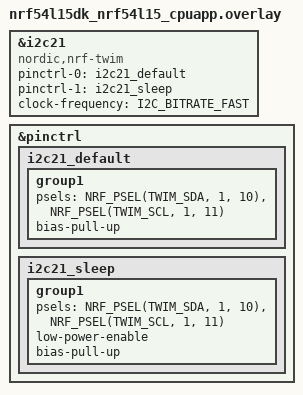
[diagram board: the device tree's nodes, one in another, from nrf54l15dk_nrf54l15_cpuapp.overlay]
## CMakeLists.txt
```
cmake_minimum_required(VERSION 3.20.0)
find_package(Zephyr REQUIRED HINTS $ENV{ZEPHYR_BASE})

project(i2c_hardtest)

target_sources(app PRIVATE src/main.c)
```

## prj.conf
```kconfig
# ==== Zephyr I2C設定（nRF54L15DK, NCS v3.2.4 向け）====

# Zephyr標準I2Cドライバを有効化
CONFIG_I2C=y

# デバッグ出力
CONFIG_PRINTK=y
CONFIG_LOG=y
CONFIG_LOG_DEFAULT_LEVEL=3

# スタック余裕
CONFIG_MAIN_STACK_SIZE=2048

# アサート
CONFIG_ASSERT=y

# UART コンソール
CONFIG_SERIAL=y
CONFIG_CONSOLE=y
CONFIG_UART_CONSOLE=y
```

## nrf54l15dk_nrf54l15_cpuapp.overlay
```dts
/* I2C設定: TWIM21を使用（UART20との競合回避） */

&i2c21 {
    status = "okay";
    compatible = "nordic,nrf-twim";
    pinctrl-0 = <&i2c21_default>;
    pinctrl-1 = <&i2c21_sleep>;
    pinctrl-names = "default", "sleep";
    clock-frequency = <I2C_BITRATE_FAST>; /* 400kHz */
};

&pinctrl {
    i2c21_default: i2c21_default {
        group1 {
            psels = <NRF_PSEL(TWIM_SDA, 1, 10)>,
                    <NRF_PSEL(TWIM_SCL, 1, 11)>;
            bias-pull-up;  /* ★ 内蔵プルアップを有効化 */
        };
    };

    i2c21_sleep: i2c21_sleep {
        group1 {
            psels = <NRF_PSEL(TWIM_SDA, 1, 10)>,
                    <NRF_PSEL(TWIM_SCL, 1, 11)>;
            low-power-enable;
            bias-pull-up;  /* ★ スリープ時もプルアップを維持 */
        };
    };
};
```

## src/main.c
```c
#include <zephyr/kernel.h>
#include <zephyr/device.h>
#include <zephyr/drivers/i2c.h>
#include <zephyr/sys/printk.h>

/* I2Cデバイスノード（TWIM21を使用） */
#define I2C_DEV_NODE DT_NODELABEL(i2c21)

/* スレーブアドレス（7bit） */
#define I2C_ADDR_7BIT  0x50

/* 送信データ（0～255） */
static uint8_t tx_buf[256];

int main(void)
{
    const struct device *i2c_dev;
    int ret;
    uint32_t success_count = 0;
    uint32_t error_count = 0;

    printk("=== nRF54L15 I2C Test (TWIM21) ===\n");

    /* 送信データ初期化 */
    for (uint32_t i = 0; i < sizeof(tx_buf); i++) {
        tx_buf[i] = (uint8_t)i;
    }

    /* I2Cデバイス取得 */
    i2c_dev = DEVICE_DT_GET(I2C_DEV_NODE);
    
    if (!device_is_ready(i2c_dev)) {
        printk("ERROR: I2C device not ready\n");
        return -1;
    }

    printk("I2C device ready: %s\n", i2c_dev->name);

    /* I2C設定を表示 */
    uint32_t i2c_cfg;
    ret = i2c_get_config(i2c_dev, &i2c_cfg);
    if (ret == 0) {
        uint32_t speed = I2C_SPEED_GET(i2c_cfg);
        const char *speed_str;
        switch (speed) {
            case I2C_SPEED_STANDARD:   speed_str = "100kHz"; break;
            case I2C_SPEED_FAST:       speed_str = "400kHz"; break;
            case I2C_SPEED_FAST_PLUS:  speed_str = "1MHz"; break;
            default:                   speed_str = "unknown"; break;
        }
        printk("I2C speed: %s\n", speed_str);
    }


    printk("Starting I2C transmission to addr 0x%02X...\n", I2C_ADDR_7BIT);

    /* 連続送信 */
    while (1) {


        for(int i=0;i!=sizeof(tx_buf);i++){
            ret = i2c_write(i2c_dev, &tx_buf[i], 1, I2C_ADDR_7BIT);
            
            if (ret == 0) {
                success_count++;
                if (success_count % 100 == 0) {
                    printk("OK: %u, ERR: %u\n", success_count, error_count);
                }
            } else {
                error_count++;
                if (error_count % 10 == 0) {
                    printk("I2C error: %d (total: %u)\n", ret, error_count);
                }
                //k_msleep(10);
            }
            
        }
        
        /*
        
        ret = i2c_write(i2c_dev, tx_buf, sizeof(tx_buf), I2C_ADDR_7BIT);

        if (ret == 0) {
            success_count++;
            if (success_count % 100 == 0) {
                printk("OK: %u, ERR: %u\n", success_count, error_count);
            }
        } else {
            error_count++;
            if (error_count % 10 == 0) {
                printk("I2C error: %d (total: %u)\n", ret, error_count);
            }
            k_msleep(10);
        }
            */
        
        k_yield();
    }

    return 0;
}
```
